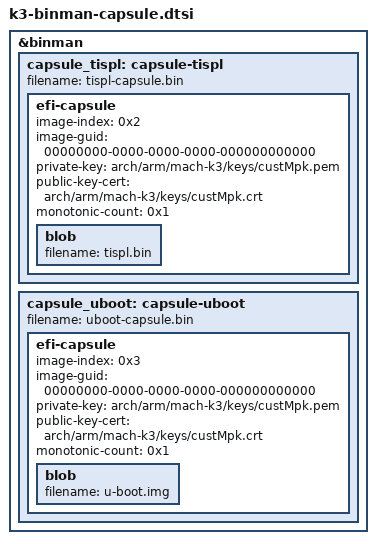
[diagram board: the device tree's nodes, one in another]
// SPDX-License-Identifier: GPL-2.0
/*
 * Copyright (C) 2024 Texas Instruments Incorporated - https://www.ti.com/
 */

&binman {
	capsule_tispl: capsule-tispl {
		filename = "tispl-capsule.bin";
		efi-capsule {
			image-index = <0x2>;
			image-guid = "00000000-0000-0000-0000-000000000000";
			private-key = "arch/arm/mach-k3/keys/custMpk.pem";
			public-key-cert = "arch/arm/mach-k3/keys/custMpk.crt";
			monotonic-count = <0x1>;

			blob {
				filename = "tispl.bin";
			};
		};
	};
};

&binman {
	capsule_uboot: capsule-uboot {
		filename = "uboot-capsule.bin";
		efi-capsule {
			image-index = <0x3>;
			image-guid = "00000000-0000-0000-0000-000000000000";
			private-key = "arch/arm/mach-k3/keys/custMpk.pem";
			public-key-cert = "arch/arm/mach-k3/keys/custMpk.crt";
			monotonic-count = <0x1>;

			blob {
				filename = "u-boot.img";
			};
		};
	};
};
